AUTOSAR XML (schema 00051)
package /Components
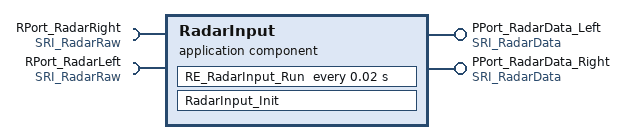
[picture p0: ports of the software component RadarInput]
  application sw component type RadarInput
    require port RPort_RadarRight: required-com-specs=[{data-element=Status_Raw, init-value=0}, {data-element=Distance_Raw, init-value=0}], required-interface=SRI_RadarRaw
    require port RPort_RadarLeft: required-com-specs=[{data-element=Status_Raw, init-value=0}, {data-element=Distance_Raw, init-value=0}], required-interface=SRI_RadarRaw
    provide port PPort_RadarData_Left: provided-com-specs=[{data-element=Status, init-value=RADAR_OK}, {data-element=Distance, init-value=0}], provided-interface=SRI_RadarData
    provide port PPort_RadarData_Right: provided-com-specs=[{data-element=Distance, init-value=0}, {data-element=Status, init-value=RADAR_OK}], provided-interface=SRI_RadarData
    behavior RadarInput_IB: data-type-mapping=bsdDataTypeMappingsSet, handle-termination-and-restart=NO-SUPPORT
      timing event TE_RadarInput_20ms: start-on-event=RE_RadarInput_Run, period=0.02
      runnable RadarInput_Init
      runnable RE_RadarInput_Run
        data-receive-point-by-arguments:
          4 x access:
            IN_RPort_RadarLeft_Distance_Raw: accessed-variable=RPort_RadarLeft.Distance_Raw
            IN_RPort_RadarRight_Distance_Raw: accessed-variable=RPort_RadarRight.Distance_Raw
            IN_RPort_RadarLeft_Status_Raw: accessed-variable=RPort_RadarLeft.Status_Raw
            IN_RPort_RadarRight_Status_Raw: accessed-variable=RPort_RadarRight.Status_Raw
        data-send-points:
          4 x access:
            OUT_PPort_RadarData_Left_Status: accessed-variable=PPort_RadarData_Left.Status
            OUT_PPort_RadarData_Left_Distance: accessed-variable=PPort_RadarData_Left.Distance
            OUT_PPort_RadarData_Right_Status: accessed-variable=PPort_RadarData_Right.Status
            OUT_PPort_RadarData_Right_Distance: accessed-variable=PPort_RadarData_Right.Distance
